AUTOSAR XML (schema 3-2-1)
package /seat-heater/Regulator_swc
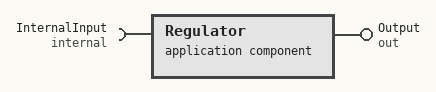
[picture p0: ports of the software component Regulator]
  application software component type Regulator
    require port InternalInput: provided-interface=internal
    provide port Output: provided-interface=out
  internal behavior RegulatorBehavior: compontent=Regulator
  swc implementation RegulatorImplementation: behavior=RegulatorBehavior
